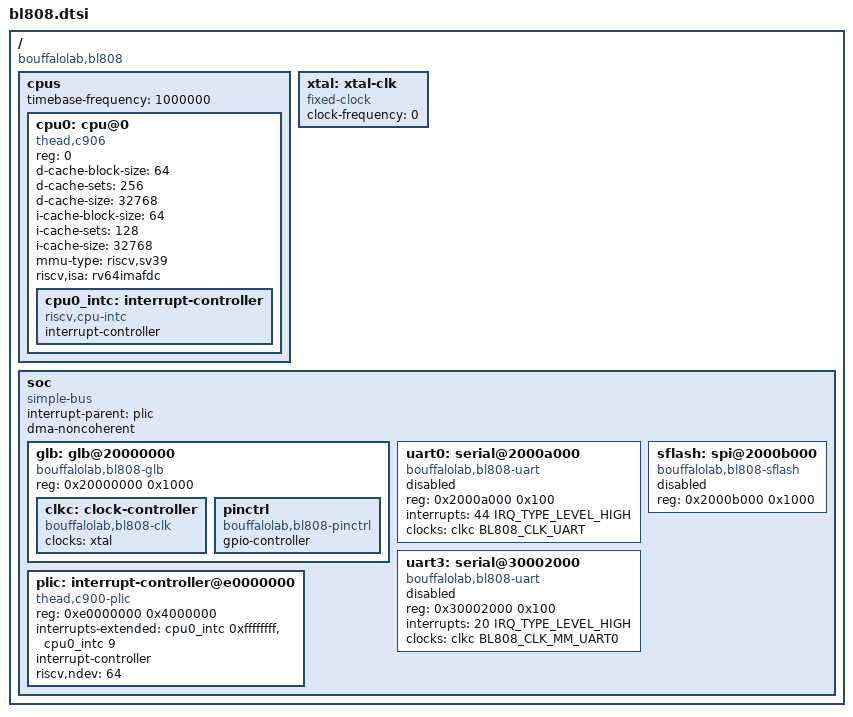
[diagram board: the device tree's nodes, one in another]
// SPDX-License-Identifier: (GPL-2.0+ or MIT)
/*
 * Copyright (C) 2022 Jisheng Zhang <jszhang@kernel.org>
 */

#include <dt-bindings/interrupt-controller/irq.h>
#include <dt-bindings/clock/bl808-clock.h>

/ {
	compatible = "bouffalolab,bl808";
	#address-cells = <1>;
	#size-cells = <1>;

	cpus {
		timebase-frequency = <1000000>;
		#address-cells = <1>;
		#size-cells = <0>;

		cpu0: cpu@0 {
			compatible = "thead,c906", "riscv";
			device_type = "cpu";
			reg = <0>;
			d-cache-block-size = <64>;
			d-cache-sets = <256>;
			d-cache-size = <32768>;
			i-cache-block-size = <64>;
			i-cache-sets = <128>;
			i-cache-size = <32768>;
			mmu-type = "riscv,sv39";
			riscv,isa = "rv64imafdc";

			cpu0_intc: interrupt-controller {
				compatible = "riscv,cpu-intc";
				interrupt-controller;
				#address-cells = <0>;
				#interrupt-cells = <1>;
			};
		};
	};

	xtal: xtal-clk {
		compatible = "fixed-clock";
		#clock-cells = <0>;
		/* This value must be overridden by the board */
		clock-frequency = <0>;
	};

	soc {
		compatible = "simple-bus";
		ranges;
		interrupt-parent = <&plic>;
		dma-noncoherent;
		#address-cells = <1>;
		#size-cells = <1>;

		glb: glb@20000000 {
			compatible = "bouffalolab,bl808-glb", "syscon", "simple-mfd";
			reg = <0x20000000 0x1000>;
			#address-cells = <1>;
			#size-cells = <1>;

			clkc: clock-controller {
				#clock-cells = <1>;
				compatible = "bouffalolab,bl808-clk";
				clocks = <&xtal>;
			};

			pinctrl: pinctrl {
				compatible = "bouffalolab,bl808-pinctrl";
				gpio-controller;
				#gpio-cells = <2>;
			};
		};

		uart0: serial@2000a000 {
			compatible = "bouffalolab,bl808-uart";
			reg = <0x2000a000 0x100>;
			interrupts = <44 IRQ_TYPE_LEVEL_HIGH>;
			clocks = <&clkc BL808_CLK_UART>;
			status = "disabled";
		};

		sflash: spi@2000b000 {
			compatible = "bouffalolab,bl808-sflash";
			reg = <0x2000b000 0x1000>;
			status = "disabled";
		};

		uart3: serial@30002000 {
			compatible = "bouffalolab,bl808-uart";
			reg = <0x30002000 0x100>;
			interrupts = <20 IRQ_TYPE_LEVEL_HIGH>;
			clocks = <&clkc BL808_CLK_MM_UART0>;
			status = "disabled";
		};

		plic: interrupt-controller@e0000000 {
			compatible = "thead,c900-plic";
			reg = <0xe0000000 0x4000000>;
			interrupts-extended = <&cpu0_intc 0xffffffff>,
					      <&cpu0_intc 9>;
			interrupt-controller;
			#address-cells = <0>;
			#interrupt-cells = <2>;
			riscv,ndev = <64>;
		};
	};
};
